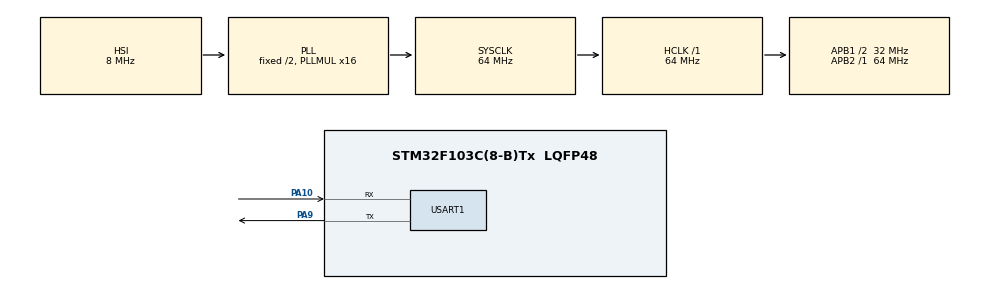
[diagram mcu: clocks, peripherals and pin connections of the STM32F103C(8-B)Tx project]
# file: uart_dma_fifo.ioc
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Mcu.Family=STM32F1
Dma.USART1_TX.1.Instance=DMA1_Channel4
NVIC.DMA1_Channel5_IRQn=true\:0\:0\:false\:false\:true\:false\:true
Dma.USART1_RX.0.PeriphDataAlignment=DMA_PDATAALIGN_BYTE
PA10.Mode=Asynchronous
Dma.USART1_TX.1.MemInc=DMA_MINC_ENABLE
RCC.APB1CLKDivider=RCC_HCLK_DIV2
RCC.SYSCLKSource=RCC_SYSCLKSOURCE_PLLCLK
ProjectManager.StackSize=0x400
PA13.Signal=SYS_JTMS-SWDIO
PA9.Mode=Asynchronous
ProjectManager.TargetToolchain=STM32CubeIDE
Dma.USART1_RX.0.Direction=DMA_PERIPH_TO_MEMORY
RCC.HCLKFreq_Value=64000000
RCC.APB2TimFreq_Value=64000000
PA9.Signal=USART1_TX
RCC.USBFreq_Value=64000000
TIM4.Prescaler=31
RCC.AHBFreq_Value=64000000
Dma.USART1_RX.0.Priority=DMA_PRIORITY_LOW
Dma.USART1_RX.0.PeriphInc=DMA_PINC_DISABLE
Dma.USART1_TX.1.MemDataAlignment=DMA_MDATAALIGN_BYTE
board=custom
RCC.PLLMUL=RCC_PLL_MUL16
RCC.APB2Freq_Value=64000000
PA14.Mode=Serial_Wire
Dma.USART1_RX.0.MemDataAlignment=DMA_MDATAALIGN_BYTE
TIM4.Period=999
Dma.USART1_RX.0.MemInc=DMA_MINC_ENABLE
PA13.Mode=Serial_Wire
Mcu.Name=STM32F103C(8-B)Tx
Dma.USART1_TX.1.PeriphDataAlignment=DMA_PDATAALIGN_BYTE
RCC.SYSCLKFreq_VALUE=64000000
Mcu.Package=LQFP48
Dma.USART1_TX.1.Mode=DMA_NORMAL
USART1.VirtualMode=VM_ASYNC
PA10.Signal=USART1_RX
PA14.Signal=SYS_JTCK-SWCLK
ProjectManager.HeapSize=0x200
Dma.USART1_TX.1.PeriphInc=DMA_PINC_DISABLE
VP_TIM4_VS_ClockSourceINT.Mode=Internal
NVIC.PriorityGroup=NVIC_PRIORITYGROUP_4
Dma.Request1=USART1_TX
RCC.APB1TimFreq_Value=64000000
Dma.USART1_RX.0.Mode=DMA_CIRCULAR
Dma.USART1_TX.1.Priority=DMA_PRIORITY_LOW
NVIC.DMA1_Channel4_IRQn=true\:0\:0\:false\:false\:true\:false\:true
NVIC.USART1_IRQn=true\:0\:0\:false\:false\:true\:true\:true
NVIC.TIM4_IRQn=true\:0\:0\:false\:false\:true\:true\:true
Dma.Request0=USART1_RX
RCC.APB1Freq_Value=32000000
Dma.USART1_RX.0.Instance=DMA1_Channel5
Dma.USART1_TX.1.Direction=DMA_MEMORY_TO_PERIPH

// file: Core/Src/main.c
/* USER CODE BEGIN Header */
/**
  ******************************************************************************
  * @file           : main.c
  * @brief          : Main program body
  ******************************************************************************
  * @attention
  *
  * <h2><center>&copy; Copyright (c) 2021 STMicroelectronics.
  * All rights reserved.</center></h2>
  *
  * This software component is licensed by ST under BSD 3-Clause license,
  * the "License"; You may not use this file except in compliance with the
  * License. You may obtain a copy of the License at:
  *                        opensource.org/licenses/BSD-3-Clause
  *
  ******************************************************************************
  */
/* USER CODE END Header */
#include "main.h"

/* USER CODE BEGIN Includes */
#include "serial.h"
/* USER CODE END Includes */

TIM_HandleTypeDef htim4;

UART_HandleTypeDef huart1;
DMA_HandleTypeDef hdma_usart1_rx;
DMA_HandleTypeDef hdma_usart1_tx;

void SystemClock_Config(void);
static void MX_GPIO_Init(void);
static void MX_DMA_Init(void);
static void MX_USART1_UART_Init(void);
static void MX_TIM4_Init(void);

int main(void)
{

  /* MCU Configuration--------------------------------------------------------*/

  /* Reset of all peripherals, Initializes the Flash interface and the Systick. */
  HAL_Init();

  /* Configure the system clock */
  SystemClock_Config();

  /* Initialize all configured peripherals */
  MX_GPIO_Init();
  MX_DMA_Init();
  MX_USART1_UART_Init();
  MX_TIM4_Init();
  /* USER CODE BEGIN 2 */
  serial_drv_init(&huart1);
  HAL_TIM_Base_Start_IT(&htim4);
  /* USER CODE END 2 */

  /* Infinite loop */
  while (1)
  {

  }
}

void SystemClock_Config(void)
{
  RCC_OscInitTypeDef RCC_OscInitStruct = {0};
  RCC_ClkInitTypeDef RCC_ClkInitStruct = {0};

  /** Initializes the RCC Oscillators according to the specified parameters
  * in the RCC_OscInitTypeDef structure.
  */
  RCC_OscInitStruct.OscillatorType = RCC_OSCILLATORTYPE_HSI;
  RCC_OscInitStruct.HSIState = RCC_HSI_ON;
  RCC_OscInitStruct.HSICalibrationValue = RCC_HSICALIBRATION_DEFAULT;
  RCC_OscInitStruct.PLL.PLLState = RCC_PLL_ON;
  RCC_OscInitStruct.PLL.PLLSource = RCC_PLLSOURCE_HSI_DIV2;
  RCC_OscInitStruct.PLL.PLLMUL = RCC_PLL_MUL16;
  if (HAL_RCC_OscConfig(&RCC_OscInitStruct) != HAL_OK)
  {
    Error_Handler();
  }
  /** Initializes the CPU, AHB and APB buses clocks
  */
  RCC_ClkInitStruct.ClockType = RCC_CLOCKTYPE_HCLK|RCC_CLOCKTYPE_SYSCLK
                              |RCC_CLOCKTYPE_PCLK1|RCC_CLOCKTYPE_PCLK2;
  RCC_ClkInitStruct.SYSCLKSource = RCC_SYSCLKSOURCE_PLLCLK;
  RCC_ClkInitStruct.AHBCLKDivider = RCC_SYSCLK_DIV1;
  RCC_ClkInitStruct.APB1CLKDivider = RCC_HCLK_DIV2;
  RCC_ClkInitStruct.APB2CLKDivider = RCC_HCLK_DIV1;

  if (HAL_RCC_ClockConfig(&RCC_ClkInitStruct, FLASH_LATENCY_2) != HAL_OK)
  {
    Error_Handler();
  }
}

static void MX_TIM4_Init(void)
{

  TIM_ClockConfigTypeDef sClockSourceConfig = {0};
  TIM_MasterConfigTypeDef sMasterConfig = {0};

  htim4.Instance = TIM4;
  htim4.Init.Prescaler = 31;
  htim4.Init.CounterMode = TIM_COUNTERMODE_UP;
  htim4.Init.Period = 999;
  htim4.Init.ClockDivision = TIM_CLOCKDIVISION_DIV1;
  htim4.Init.AutoReloadPreload = TIM_AUTORELOAD_PRELOAD_DISABLE;
  if (HAL_TIM_Base_Init(&htim4) != HAL_OK)
  {
    Error_Handler();
  }
  sClockSourceConfig.ClockSource = TIM_CLOCKSOURCE_INTERNAL;
  if (HAL_TIM_ConfigClockSource(&htim4, &sClockSourceConfig) != HAL_OK)
  {
    Error_Handler();
  }
  sMasterConfig.MasterOutputTrigger = TIM_TRGO_RESET;
  sMasterConfig.MasterSlaveMode = TIM_MASTERSLAVEMODE_DISABLE;
  if (HAL_TIMEx_MasterConfigSynchronization(&htim4, &sMasterConfig) != HAL_OK)
  {
    Error_Handler();
  }

}

static void MX_USART1_UART_Init(void)
{

  huart1.Instance = USART1;
  huart1.Init.BaudRate = 115200;
  huart1.Init.WordLength = UART_WORDLENGTH_8B;
  huart1.Init.StopBits = UART_STOPBITS_1;
  huart1.Init.Parity = UART_PARITY_NONE;
  huart1.Init.Mode = UART_MODE_TX_RX;
  huart1.Init.HwFlowCtl = UART_HWCONTROL_NONE;
  huart1.Init.OverSampling = UART_OVERSAMPLING_16;
  if (HAL_UART_Init(&huart1) != HAL_OK)
  {
    Error_Handler();
  }

}

static void MX_DMA_Init(void)
{

  /* DMA controller clock enable */
  __HAL_RCC_DMA1_CLK_ENABLE();

  /* DMA interrupt init */
  /* DMA1_Channel4_IRQn interrupt configuration */
  HAL_NVIC_SetPriority(DMA1_Channel4_IRQn, 0, 0);
  HAL_NVIC_EnableIRQ(DMA1_Channel4_IRQn);
  /* DMA1_Channel5_IRQn interrupt configuration */
  HAL_NVIC_SetPriority(DMA1_Channel5_IRQn, 0, 0);
  HAL_NVIC_EnableIRQ(DMA1_Channel5_IRQn);

}

static void MX_GPIO_Init(void)
{

  /* GPIO Ports Clock Enable */
  __HAL_RCC_GPIOA_CLK_ENABLE();

}

/* USER CODE BEGIN 4 */
void HAL_TIM_PeriodElapsedCallback(TIM_HandleTypeDef *htim)
{
	if (htim->Instance == htim4.Instance)
	{
		serial_drv_callback();
	}
}
/* USER CODE END 4 */

void Error_Handler(void)
{
  __disable_irq();
  while (1)
  {
  }
}

/************************ (C) COPYRIGHT STMicroelectronics *****END OF FILE****/
